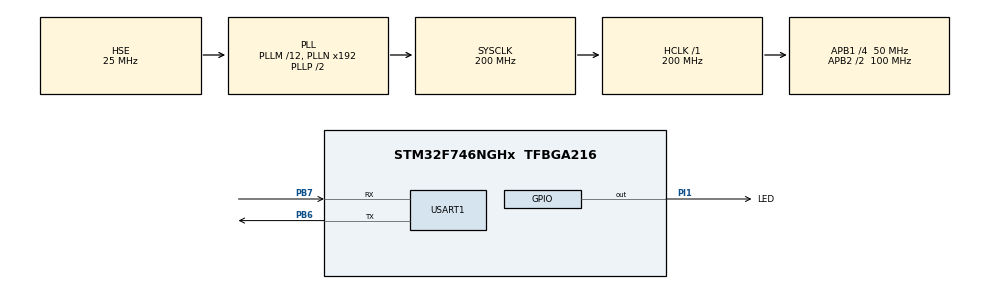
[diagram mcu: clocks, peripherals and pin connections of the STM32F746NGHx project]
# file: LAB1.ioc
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Mcu.Family=STM32F7
Mcu.Name=STM32F746NGHx
Mcu.Package=TFBGA216
NVIC.PriorityGroup=NVIC_PRIORITYGROUP_4
NVIC.TIM1_UP_TIM10_IRQn=true\:15\:0\:false\:false\:true\:false\:true
NVIC.TimeBase=TIM1_UP_TIM10_IRQn
NVIC.TimeBaseIP=TIM1
PB6.Mode=Asynchronous
PB6.Signal=USART1_TX
PB7.Mode=Asynchronous
PB7.Signal=USART1_RX
PC14/OSC32_IN.Mode=LSE-External-Oscillator
PC14/OSC32_IN.Signal=RCC_OSC32_IN
PC15/OSC32_OUT.Mode=LSE-External-Oscillator
PC15/OSC32_OUT.Signal=RCC_OSC32_OUT
PH0/OSC_IN.Mode=HSE-External-Oscillator
PH0/OSC_IN.Signal=RCC_OSC_IN
PH1/OSC_OUT.Mode=HSE-External-Oscillator
PH1/OSC_OUT.Signal=RCC_OSC_OUT
PI1.GPIO_Label=LED
PI1.GPIO_Speed=GPIO_SPEED_FREQ_VERY_HIGH
PI1.Signal=GPIO_Output
ProjectManager.HeapSize=0x200
ProjectManager.StackSize=0x400
ProjectManager.TargetToolchain=STM32CubeIDE
RCC.AHBFreq_Value=200000000
RCC.APB1CLKDivider=RCC_HCLK_DIV4
RCC.APB1Freq_Value=50000000
RCC.APB1TimFreq_Value=100000000
RCC.APB2CLKDivider=RCC_HCLK_DIV2
RCC.APB2Freq_Value=100000000
RCC.APB2TimFreq_Value=200000000
RCC.CortexFreq_Value=200000000
RCC.HCLKFreq_Value=200000000
RCC.HSE_VALUE=25000000
RCC.HSI_VALUE=16000000
RCC.PLLM=12
RCC.PLLSourceVirtual=RCC_PLLSOURCE_HSE
RCC.SYSCLKFreq_VALUE=200000000
RCC.SYSCLKSource=RCC_SYSCLKSOURCE_PLLCLK
RCC.USBFreq_Value=200000000
RCC.VCOOutputFreq_Value=400000000
USART1.VirtualMode-Asynchronous=VM_ASYNC
VP_SYS_VS_tim1.Mode=TIM1
board=STM32F746G-DISCO

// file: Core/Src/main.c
/* USER CODE BEGIN Header */
/**
 ******************************************************************************
 * @file           : main.c
 * @brief          : Main program body
 ******************************************************************************
 * @attention
 *
 * <h2><center>&copy; Copyright (c) 2023 STMicroelectronics.
 * All rights reserved.</center></h2>
 *
 * This software component is licensed by ST under BSD 3-Clause license,
 * the "License"; You may not use this file except in compliance with the
 * License. You may obtain a copy of the License at:
 *                        opensource.org/licenses/BSD-3-Clause
 *
 ******************************************************************************
 */
/* USER CODE END Header */
#include "main.h"

UART_HandleTypeDef huart1;

void SystemClock_Config(void);
static void MX_GPIO_Init(void);
static void MX_USART1_UART_Init(void);

/* USER CODE BEGIN 0 */
void SysTickDelayCount2(unsigned long);
void __attribute__((naked)) SysTickDelayCount(unsigned long);

/* USER CODE END 0 */

int main(void)
{

	/* MCU Configuration--------------------------------------------------------*/

	/* Reset of all peripherals, Initializes the Flash interface and the Systick. */
	HAL_Init();

	/* Configure the system clock */
	SystemClock_Config();

	/* Initialize all configured peripherals */
	MX_GPIO_Init();
	MX_USART1_UART_Init();
	/* USER CODE BEGIN 2 */

	volatile unsigned long * ptr;
	ptr = (uint32_t*) 0x40022018;

	/* USER CODE END 2 */

	/* Infinite loop */
	while (1)
	{

		/* USER CODE BEGIN 3 */
		/*NOTES
		 * tijd afpassen: instructies tellen 8051
		 *
		 * __attribute zeggen waar in memory iets moet staan
		 * naked : compiler mag niks extra toevoegen
		 *
		 * tijd afpassen : performance counter
		 * grote tellers even snel als cpu
		 * +1 na elke instructie
		 *
		 *
		 *
		 *
		 *
		 * */

		//routine onder test:
		*ptr = 0x00020000;
		SysTickDelayCount2(5);

		*ptr = 0x00000002;
		SysTickDelayCount2(5);

	}
	/* USER CODE END 3 */
}

void SystemClock_Config(void)
{
	RCC_OscInitTypeDef RCC_OscInitStruct = {0};
	RCC_ClkInitTypeDef RCC_ClkInitStruct = {0};
	RCC_PeriphCLKInitTypeDef PeriphClkInitStruct = {0};

	/** Configure LSE Drive Capability
	 */
	HAL_PWR_EnableBkUpAccess();
	/** Configure the main internal regulator output voltage
	 */
	__HAL_RCC_PWR_CLK_ENABLE();
	__HAL_PWR_VOLTAGESCALING_CONFIG(PWR_REGULATOR_VOLTAGE_SCALE1);
	/** Initializes the RCC Oscillators according to the specified parameters
	 * in the RCC_OscInitTypeDef structure.
	 */
	RCC_OscInitStruct.OscillatorType = RCC_OSCILLATORTYPE_HSE;
	RCC_OscInitStruct.HSEState = RCC_HSE_ON;
	RCC_OscInitStruct.PLL.PLLState = RCC_PLL_ON;
	RCC_OscInitStruct.PLL.PLLSource = RCC_PLLSOURCE_HSE;
	RCC_OscInitStruct.PLL.PLLM = 12;
	RCC_OscInitStruct.PLL.PLLN = 192;
	RCC_OscInitStruct.PLL.PLLP = RCC_PLLP_DIV2;
	RCC_OscInitStruct.PLL.PLLQ = 2;
	if (HAL_RCC_OscConfig(&RCC_OscInitStruct) != HAL_OK)
	{
		Error_Handler();
	}
	/** Activate the Over-Drive mode
	 */
	if (HAL_PWREx_EnableOverDrive() != HAL_OK)
	{
		Error_Handler();
	}
	/** Initializes the CPU, AHB and APB buses clocks
	 */
	RCC_ClkInitStruct.ClockType = RCC_CLOCKTYPE_HCLK|RCC_CLOCKTYPE_SYSCLK
			|RCC_CLOCKTYPE_PCLK1|RCC_CLOCKTYPE_PCLK2;
	RCC_ClkInitStruct.SYSCLKSource = RCC_SYSCLKSOURCE_PLLCLK;
	RCC_ClkInitStruct.AHBCLKDivider = RCC_SYSCLK_DIV1;
	RCC_ClkInitStruct.APB1CLKDivider = RCC_HCLK_DIV4;
	RCC_ClkInitStruct.APB2CLKDivider = RCC_HCLK_DIV2;

	if (HAL_RCC_ClockConfig(&RCC_ClkInitStruct, FLASH_LATENCY_6) != HAL_OK)
	{
		Error_Handler();
	}
	PeriphClkInitStruct.PeriphClockSelection = RCC_PERIPHCLK_USART1;
	PeriphClkInitStruct.Usart1ClockSelection = RCC_USART1CLKSOURCE_PCLK2;
	if (HAL_RCCEx_PeriphCLKConfig(&PeriphClkInitStruct) != HAL_OK)
	{
		Error_Handler();
	}
}

static void MX_USART1_UART_Init(void)
{

	huart1.Instance = USART1;
	huart1.Init.BaudRate = 115200;
	huart1.Init.WordLength = UART_WORDLENGTH_8B;
	huart1.Init.StopBits = UART_STOPBITS_1;
	huart1.Init.Parity = UART_PARITY_NONE;
	huart1.Init.Mode = UART_MODE_TX_RX;
	huart1.Init.HwFlowCtl = UART_HWCONTROL_NONE;
	huart1.Init.OverSampling = UART_OVERSAMPLING_16;
	huart1.Init.OneBitSampling = UART_ONE_BIT_SAMPLE_DISABLE;
	huart1.AdvancedInit.AdvFeatureInit = UART_ADVFEATURE_NO_INIT;
	if (HAL_UART_Init(&huart1) != HAL_OK)
	{
		Error_Handler();
	}

}

static void MX_GPIO_Init(void)
{
	GPIO_InitTypeDef GPIO_InitStruct = {0};

	/* GPIO Ports Clock Enable */
	__HAL_RCC_GPIOB_CLK_ENABLE();
	__HAL_RCC_GPIOI_CLK_ENABLE();
	__HAL_RCC_GPIOC_CLK_ENABLE();
	__HAL_RCC_GPIOH_CLK_ENABLE();

	/*Configure GPIO pin Output Level */
	HAL_GPIO_WritePin(LED_GPIO_Port, LED_Pin, GPIO_PIN_RESET);

	/*Configure GPIO pin : LED_Pin */
	GPIO_InitStruct.Pin = LED_Pin;
	GPIO_InitStruct.Mode = GPIO_MODE_OUTPUT_PP;
	GPIO_InitStruct.Pull = GPIO_NOPULL;
	GPIO_InitStruct.Speed = GPIO_SPEED_FREQ_VERY_HIGH;
	HAL_GPIO_Init(LED_GPIO_Port, &GPIO_InitStruct);

}

/* USER CODE BEGIN 4 */

void SysTickDelayCount2(unsigned long ulCount){
	CoreDebug->DEMCR |= CoreDebug_DEMCR_TRCENA_Msk;
	DWT->LAR = 0xC5ACCE55;
	DWT->CYCCNT = 0;
	DWT->CTRL |= DWT_CTRL_CYCCNTENA_Msk;

	while(DWT->CYCCNT < ulCount);
}

//Delay is 1 cycle  * 1/CLOCK * Count voor M7
void __attribute__((naked)) SysTickDelayCount(unsigned long ulCount)
								{
	__asm("    subs    r0, #1\n"
			"    bne.n     SysTickDelayCount\n"
			"    bx      lr");
								}

/* USER CODE END 4 */

void HAL_TIM_PeriodElapsedCallback(TIM_HandleTypeDef *htim)
{
	if (htim->Instance == TIM1) {
		HAL_IncTick();
	}
}

void Error_Handler(void)
{
	__disable_irq();
	while (1)
	{
	}
}

/************************ (C) COPYRIGHT STMicroelectronics *****END OF FILE****/
